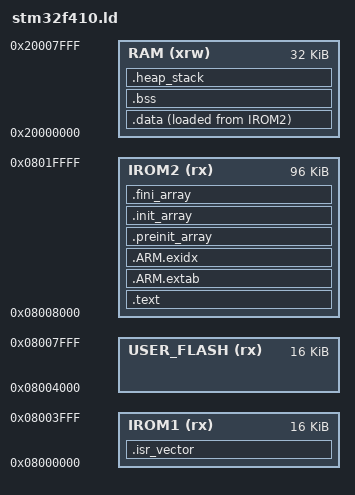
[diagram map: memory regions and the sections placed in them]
ENTRY(Reset_Handler)

MEMORY
{
  IROM1      (rx)  : ORIGIN = 0x08000000, LENGTH = 16K
  USER_FLASH (rx)  : ORIGIN = 0x08004000, LENGTH = 16K
  IROM2      (rx)  : ORIGIN = 0x08008000, LENGTH = 96K
  RAM        (xrw) : ORIGIN = 0x20000000, LENGTH = 32K
}

_estack = ORIGIN(RAM) + LENGTH(RAM);

SECTIONS
{
  .isr_vector :
  {
    KEEP(*(.isr_vector))
    KEEP(*(.vectors))
  } > IROM1

  .text :
  {
    . = ALIGN(4);
    *(.text*)
    *(.rodata*)
    *(.glue_7)
    *(.glue_7t)

    KEEP(*(.init))
    KEEP(*(.fini))

    . = ALIGN(4);
    _etext = .;
  } > IROM2

  .ARM.extab :
  {
    *(.ARM.extab* .gnu.linkonce.armextab.*)
  } > IROM2

  .ARM.exidx :
  {
    __exidx_start = .;
    *(.ARM.exidx* .gnu.linkonce.armexidx.*)
    __exidx_end = .;
  } > IROM2

  .preinit_array :
  {
    PROVIDE_HIDDEN(__preinit_array_start = .);
    KEEP(*(.preinit_array*))
    PROVIDE_HIDDEN(__preinit_array_end = .);
  } > IROM2

  .init_array :
  {
    PROVIDE_HIDDEN(__init_array_start = .);
    KEEP(*(SORT(.init_array.*)))
    KEEP(*(.init_array*))
    PROVIDE_HIDDEN(__init_array_end = .);
  } > IROM2

  .fini_array :
  {
    PROVIDE_HIDDEN(__fini_array_start = .);
    KEEP(*(SORT(.fini_array.*)))
    KEEP(*(.fini_array*))
    PROVIDE_HIDDEN(__fini_array_end = .);
  } > IROM2

  .data :
  {
    . = ALIGN(4);
    _sdata = .;
    *(.data*)
    . = ALIGN(4);
    _edata = .;
  } > RAM AT> IROM2

  _sidata = LOADADDR(.data);

  .bss :
  {
    . = ALIGN(4);
    _sbss = .;
    *(.bss*)
    *(COMMON)
    . = ALIGN(4);
    _ebss = .;
  } > RAM

  .heap_stack :
  {
    . = ALIGN(8);
    _end = .;
    end = .;
  } > RAM
}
